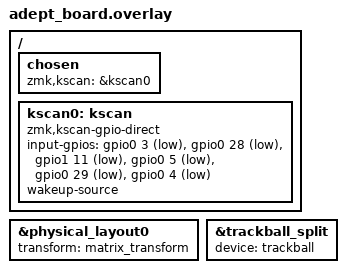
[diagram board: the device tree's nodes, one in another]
#include "adept.dtsi"
#include "pmw3610.dtsi"
#include "adept-layouts.dtsi"

&physical_layout0 {
    transform = <&matrix_transform>;
};

/ {
    chosen {
        zmk,kscan = &kscan0;
    };

    kscan0: kscan {
        compatible = "zmk,kscan-gpio-direct";
        input-gpios =
            <&gpio0  3 (GPIO_ACTIVE_LOW | GPIO_PULL_UP)>,
            <&gpio0 28 (GPIO_ACTIVE_LOW | GPIO_PULL_UP)>,
            <&gpio1 11 (GPIO_ACTIVE_LOW | GPIO_PULL_UP)>,
            <&gpio0  5 (GPIO_ACTIVE_LOW | GPIO_PULL_UP)>,
            <&gpio0 29 (GPIO_ACTIVE_LOW | GPIO_PULL_UP)>,
            <&gpio0  4 (GPIO_ACTIVE_LOW | GPIO_PULL_UP)>;
        wakeup-source;
    };
};

&trackball_split {
    device = <&trackball>;
};
